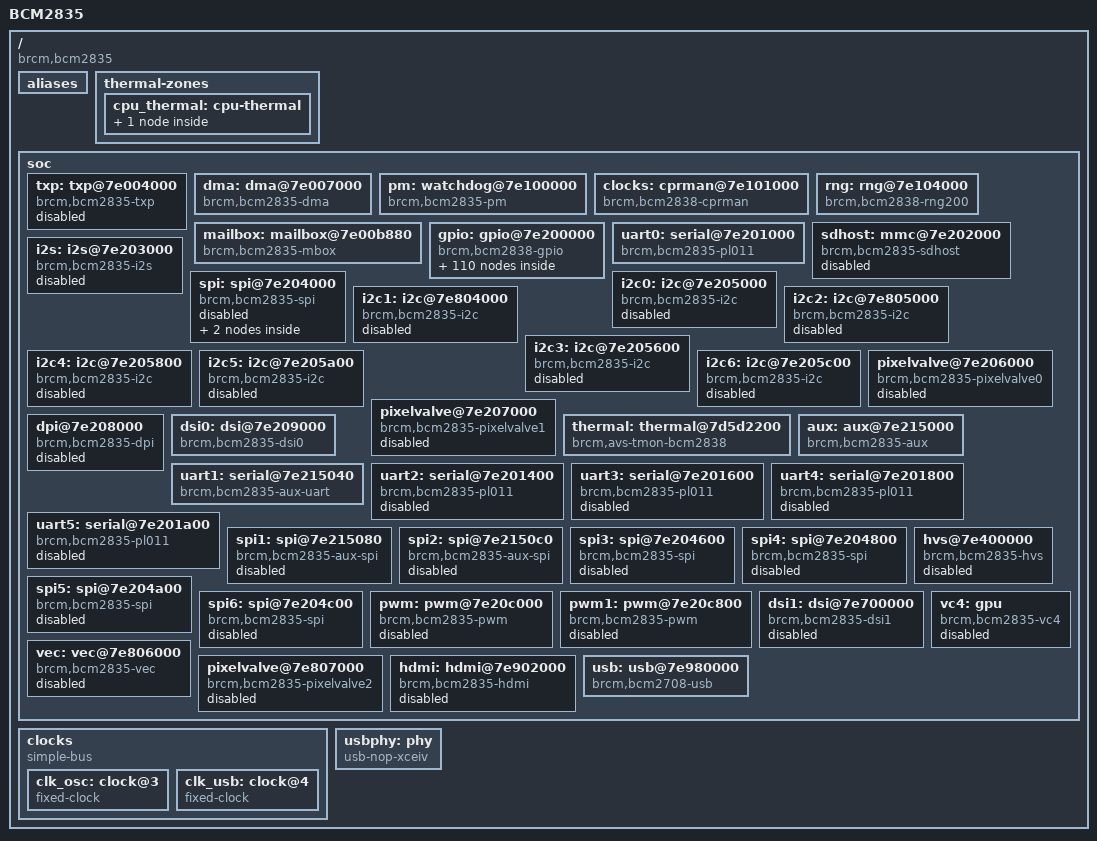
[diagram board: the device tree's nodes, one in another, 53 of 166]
#include <dt-bindings/pinctrl/bcm2835.h>
#include <dt-bindings/clock/bcm2835.h>
#include <dt-bindings/clock/bcm2835-aux.h>
#include <dt-bindings/gpio/gpio.h>
#include <dt-bindings/soc/bcm2835-pm.h>
#include <dt-bindings/interrupt-controller/arm-gic.h>
#include <dt-bindings/interrupt-controller/irq.h>
#include <dt-bindings/power/raspberrypi-power.h>

/* firmware-provided startup stubs live here, where the secondary CPUs are
 * spinning.
 */
/memreserve/ 0x00000000 0x00001000;
// /memreserve/	0x0000000000000000 0x0000000000001000;

/* This include file covers the common peripherals and configuration between
 * bcm2835 and bcm2836 implementations, leaving the CPU configuration to
 * bcm2835.dtsi and bcm2836.dtsi.
 */

/ {
	compatible = "brcm,bcm2835";
	model = "BCM2835";
	interrupt-parent = <&gicv2>;
	#address-cells = <2>;
	#size-cells = <1>;

	aliases {
		serial0 = &uart0;
		serial1 = &uart1;
	};

	// chosen {
	// 	stdout-path = "serial0:115200n8";
	// };

	thermal-zones {
		cpu_thermal: cpu-thermal {
			polling-delay-passive = <0>;
			polling-delay = <1000>;

			thermal-sensors = <&thermal>;

			coefficients = <(-487) 410040>;
			// phandle = < 0x30 >;

			// trips { // TODO:
			// 	cpu-crit {
			// 		temperature	= <80000>;
			// 		hysteresis	= <0>;
			// 		type		= "critical";
			// 	};
			// };

			cooling-maps {
			};
		};
	};

	soc {
		txp: txp@7e004000 {
			compatible = "brcm,bcm2835-txp";
			reg = < 0x7e004000 0x20 >;
			interrupts = <GIC_SPI 75 IRQ_TYPE_LEVEL_HIGH >;
			status = "disabled";
			// phandle = < 0x32 >;
		};


		dma: dma@7e007000 {
			compatible = "brcm,bcm2835-dma";
			reg = < 0x7e007000 0xb00 >;
			interrupts = <GIC_SPI 80 IRQ_TYPE_LEVEL_HIGH>, // 80
                         <GIC_SPI 81 IRQ_TYPE_LEVEL_HIGH>, // 81
                         <GIC_SPI 82 IRQ_TYPE_LEVEL_HIGH>, // 82
                         <GIC_SPI 83 IRQ_TYPE_LEVEL_HIGH>, // 83
                         <GIC_SPI 84 IRQ_TYPE_LEVEL_HIGH>, // 84
                         <GIC_SPI 85 IRQ_TYPE_LEVEL_HIGH>, // 85
                         <GIC_SPI 86 IRQ_TYPE_LEVEL_HIGH>, // 86
                         // 
                         <GIC_SPI 87 IRQ_TYPE_LEVEL_HIGH>, // 87
                         <GIC_SPI 87 IRQ_TYPE_LEVEL_HIGH>, // 87
                         //
                         <GIC_SPI 88 IRQ_TYPE_LEVEL_HIGH>, // 88
                         <GIC_SPI 88 IRQ_TYPE_LEVEL_HIGH>; // 88
			interrupt-names = "dma0", 
                              "dma1",
                              "dma2",
                              "dma3",
                              "dma4",
                              "dma5",
                              "dma6",
                              "dma7",
                              "dma8",
                              "dma9",
                              "dma10";

			#dma-cells = <1>;
			brcm,dma-channel-mask = < 0x1f5 >;
			// phandle = < 0x0a >;
		};

		pm: watchdog@7e100000 {
			compatible = "brcm,bcm2835-pm", "brcm,bcm2835-pm-wdt";
			#power-domain-cells = <1>;
			#reset-cells = <1>;
			reg = < 0x7e100000 0x114>,
			      < 0x7e00a000 0x24>,
				  < 0x7ec11000 0x20>;
			// clocks = < 0x03 0x15 0x03 0x1d 0x03 0x17 0x03 0x16 >;
			clocks = <&clocks BCM2835_CLOCK_V3D>,
				 <&clocks BCM2835_CLOCK_PERI_IMAGE>,
				 <&clocks BCM2835_CLOCK_H264>,
				 <&clocks BCM2835_CLOCK_ISP>;
			clock-names = "v3d", "peri_image", "h264", "isp";
			system-power-controller;
			// phandle = < 0x1d >;
		};

		clocks: cprman@7e101000 {
			compatible = "brcm,bcm2838-cprman";
			#clock-cells = <1>;
			reg = < 0x7e101000 0x2000 >;


			/* CPRMAN derives almost everything from the
			 * platform's oscillator.  However, the DSI
			 * pixel clocks come from the DSI analog PHY.
			 */	
			clocks = <&clk_osc>,
				<&dsi0 0>, <&dsi0 1>, <&dsi0 2>,
				<&dsi1 0>, <&dsi1 1>, <&dsi1 2>;			 
			// clocks = < 0x04 
			//            0x05 0x00 
			//            0x05 0x01 
			// 		   0x05 0x02 
					   
			// 		   0x06 0x00 
			// 		   0x06 0x01 
			// 		   0x06 0x02 >;

			firmware = <&firmware>;


			// phandle = < 0x03 >;
		};

		rng: rng@7e104000 {
			compatible = "brcm,bcm2838-rng200";
			reg = < 0x7e104000 0x10 >;
			interrupts = <GIC_SPI 125 IRQ_TYPE_LEVEL_HIGH>;
			// phandle = < 0x27 >;
		};

		mailbox: mailbox@7e00b880 {
			compatible = "brcm,bcm2835-mbox";
			reg = < 0x7e00b880 0x40 >;
			interrupts = <GIC_SPI 33 IRQ_TYPE_LEVEL_HIGH>;
			#mbox-cells = <0>;
			//phandle = < 0x1b >;
		};

		gpio: gpio@7e200000 {
			compatible = "brcm,bcm2838-gpio", "brcm,bcm2835-gpio";
			reg = < 0x7e200000 0xb4 >;
			/*
			 * The GPIO IP block is designed for 3 banks of GPIOs.
			 * Each bank has a GPIO interrupt for itself.
			 * There is an overall "any bank" interrupt.
			 * In order, these are GIC interrupts 17, 18, 19, 20.
			 * Since the BCM2835 only has 2 banks, the 2nd bank
			 * interrupt output appears to be mirrored onto the
			 * 3rd bank's interrupt signal.
			 * So, a bank0 interrupt shows up on 17, 20, and
			 * a bank1 interrupt shows up on 18, 19, 20!
			 */
			interrupts = <GIC_SPI 113 IRQ_TYPE_LEVEL_HIGH>,
                         <GIC_SPI 114 IRQ_TYPE_LEVEL_HIGH>;

			gpio-controller;
			#gpio-cells = <2>;

			interrupt-controller;
			#interrupt-cells = <2>;

			pinctrl-names = "default";
			// phandle = < 0x0f >;

			/* Defines pin muxing groups according to
			 * BCM2835-ARM-Peripherals.pdf page 102.
			 *
			 * While each pin can have its mux selected
			 * for various functions individually, some
			 * groups only make sense to switch to a
			 * particular function together.
			 */
			dpi_gpio0: dpi_gpio0 {
				brcm,pins = <0 1 2 3 4 5 6 7 8 9 10 11
					     12 13 14 15 16 17 18 19
					     20 21 22 23 24 25 26 27>;
				brcm,function = <BCM2835_FSEL_ALT2>;
				// phandle = < 0x33 >;
			};

			emmc_gpio22: emmc_gpio22 {
				brcm,pins = <22 23 24 25 26 27>;
				brcm,function = <BCM2835_FSEL_ALT3>;
				//phandle = < 0x34 >;
			};

			emmc_gpio34: emmc_gpio34 {
				brcm,pins = <34 35 36 37 38 39>;
				brcm,function = <BCM2835_FSEL_ALT3>;
				brcm,pull = <BCM2835_PUD_OFF
					     BCM2835_PUD_UP
					     BCM2835_PUD_UP
					     BCM2835_PUD_UP
					     BCM2835_PUD_UP
					     BCM2835_PUD_UP>;
				// phandle = < 0x35 >;
			};
            // ==========================================================
			emmc_gpio48: emmc_gpio48 {
				brcm,pins = <48 49 50 51 52 53>;
				brcm,function = <BCM2835_FSEL_ALT3>;
			};

			gpclk0_gpio4: gpclk0_gpio4 {
				brcm,pins = <4>;
				brcm,function = <BCM2835_FSEL_ALT0>;
			};

			gpclk1_gpio5: gpclk1_gpio5 {
				brcm,pins = <5>;
				brcm,function = <BCM2835_FSEL_ALT0>;
			};

			gpclk1_gpio42: gpclk1_gpio42 {
				brcm,pins = <42>;
				brcm,function = <BCM2835_FSEL_ALT0>;
			};

			gpclk1_gpio44: gpclk1_gpio44 {
				brcm,pins = <44>;
				brcm,function = <BCM2835_FSEL_ALT0>;
			};

			gpclk2_gpio6: gpclk2_gpio6 {
				brcm,pins = <6>;
				brcm,function = <BCM2835_FSEL_ALT0>;
			};

			gpclk2_gpio43: gpclk2_gpio43 {
				brcm,pins = <43>;
				brcm,function = <BCM2835_FSEL_ALT0>;
				brcm,pull = <BCM2835_PUD_OFF>;
			};

			i2c0_gpio0: i2c0_gpio0 {
				brcm,pins = <0 1>;
				brcm,function = <BCM2835_FSEL_ALT0>;
			};

			i2c0_gpio28: i2c0_gpio28 {
				brcm,pins = <28 29>;
				brcm,function = <BCM2835_FSEL_ALT0>;
			};

			i2c0_gpio44: i2c0_gpio44 {
				brcm,pins = <44 45>;
				brcm,function = <BCM2835_FSEL_ALT1>;
			};

			i2c1_gpio2: i2c1_gpio2 {
				brcm,pins = <2 3>;
				brcm,function = <BCM2835_FSEL_ALT0>;
			};

			i2c1_gpio44: i2c1_gpio44 {
				brcm,pins = <44 45>;
				brcm,function = <BCM2835_FSEL_ALT2>;
			};

			jtag_gpio22: jtag_gpio22 {
				brcm,pins = <22 23 24 25 26 27>;
				brcm,function = <BCM2835_FSEL_ALT4>;
			};

			pcm_gpio18: pcm_gpio18 {
				brcm,pins = <18 19 20 21>;
				brcm,function = <BCM2835_FSEL_ALT0>;
			};

			pcm_gpio28: pcm_gpio28 {
				brcm,pins = <28 29 30 31>;
				brcm,function = <BCM2835_FSEL_ALT2>;
			};

			pwm0_gpio12: pwm0_gpio12 {
				brcm,pins = <12>;
				brcm,function = <BCM2835_FSEL_ALT0>;
			};

			pwm0_gpio18: pwm0_gpio18 {
				brcm,pins = <18>;
				brcm,function = <BCM2835_FSEL_ALT5>;
			};

			pwm0_gpio40: pwm0_gpio40 {
				brcm,pins = <40>;
				brcm,function = <BCM2835_FSEL_ALT0>;
			};

			pwm1_gpio13: pwm1_gpio13 {
				brcm,pins = <13>;
				brcm,function = <BCM2835_FSEL_ALT0>;
			};

			pwm1_gpio19: pwm1_gpio19 {
				brcm,pins = <19>;
				brcm,function = <BCM2835_FSEL_ALT5>;
			};

			pwm1_gpio41: pwm1_gpio41 {
				brcm,pins = <41>;
				brcm,function = <BCM2835_FSEL_ALT0>;
			};

			pwm1_gpio45: pwm1_gpio45 {
				brcm,pins = <45>;
				brcm,function = <BCM2835_FSEL_ALT0>;
			};

			sdhost_gpio48: sdhost_gpio48 { // TODO: why? pin 22...
				brcm,pins = <22 23 24 25 26 27>;
				brcm,function = <BCM2835_FSEL_ALT0>;
			};

			spi0_gpio7: spi0_gpio7 {
				brcm,pins = <7 8 9 10 11>;
				brcm,function = <BCM2835_FSEL_ALT0>;
			};

			spi0_gpio35: spi0_gpio35 {
				brcm,pins = <35 36 37 38 39>;
				brcm,function = <BCM2835_FSEL_ALT0>;
			};

			spi1_gpio16: spi1_gpio16 {
				brcm,pins = <16 17 18 19 20 21>;
				brcm,function = <BCM2835_FSEL_ALT4>;
			};

			spi2_gpio40: spi2_gpio40 {
				brcm,pins = <40 41 42 43 44 45>;
				brcm,function = <BCM2835_FSEL_ALT4>;
			};

			uart0_gpio14: uart0_gpio14 {
				brcm,pins = <14 15>;
				brcm,function = <BCM2835_FSEL_ALT0>;
			};

			uart0_ctsrts_gpio16: uart0_ctsrts_gpio16 {
				brcm,pins = <16 17>;
				brcm,function = <BCM2835_FSEL_ALT3>;
			};

			uart0_ctsrts_gpio30: uart0_ctsrts_gpio30 {
				brcm,pins = <30 31>;
				brcm,function = <BCM2835_FSEL_ALT3>;
				brcm,pull = <BCM2835_PUD_UP BCM2835_PUD_OFF>;
			};

			uart0_gpio32: uart0_gpio32 {
				brcm,pins = <32 33>;
				brcm,function = <BCM2835_FSEL_ALT3>;
				brcm,pull = <BCM2835_PUD_OFF BCM2835_PUD_UP>;
			};

			uart0_gpio36: uart0_gpio36 {
				brcm,pins = <36 37>;
				brcm,function = <BCM2835_FSEL_ALT2>;
			};

			uart0_ctsrts_gpio38: uart0_ctsrts_gpio38 {
				brcm,pins = <38 39>;
				brcm,function = <BCM2835_FSEL_ALT2>;
			};

			uart1_gpio14: uart1_gpio14 {
				brcm,pins = <14 15>;
				brcm,function = <BCM2835_FSEL_ALT5>;
			};

			uart1_ctsrts_gpio16: uart1_ctsrts_gpio16 {
				brcm,pins = <16 17>;
				brcm,function = <BCM2835_FSEL_ALT5>;
			};

			uart1_gpio32: uart1_gpio32 {
				brcm,pins = <32 33>;
				brcm,function = <BCM2835_FSEL_ALT5>;
			};

			uart1_ctsrts_gpio30: uart1_ctsrts_gpio30 {
				brcm,pins = <30 31>;
				brcm,function = <BCM2835_FSEL_ALT5>;
			};

			uart1_gpio40: uart1_gpio40 {
				brcm,pins = <40 41>;
				brcm,function = <BCM2835_FSEL_ALT5>;
			};

			uart1_ctsrts_gpio42: uart1_ctsrts_gpio42 {
				brcm,pins = <42 43>;
				brcm,function = <BCM2835_FSEL_ALT5>;
			};

			gpclk0_gpio49: gpclk0_gpio49 {
				brcm,pins = <49>;
				brcm,function = <BCM2835_FSEL_ALT1>;
				brcm,pull = <BCM2835_PUD_OFF>;
			};

			gpclk1_gpio50: gpclk1_gpio50 {
				brcm,pins = <50>;
				brcm,function = <BCM2835_FSEL_ALT1>;
				brcm,pull = <BCM2835_PUD_OFF>;
			};

			gpclk2_gpio51: gpclk2_gpio51 {
				brcm,pins = <51>;
				brcm,function = <BCM2835_FSEL_ALT1>;
				brcm,pull = <BCM2835_PUD_OFF >;
			};

			i2c0_gpio46: i2c0_gpio46 {
				brcm,pins = <46 47>;
				brcm,function = <BCM2835_FSEL_ALT0>;
			};

			i2c1_gpio46: i2c1_gpio46 {
				brcm,pins = <46 47>;
				brcm,function = <BCM2835_FSEL_ALT1>;
			};

			i2c3_gpio2: i2c3_gpio2 {
				brcm,pins = <2 3>;
				brcm,function = <BCM2835_FSEL_ALT5>;
			};

			i2c3_gpio4: i2c3_gpio4 {
				brcm,pins = <4 5>;
				brcm,function = <BCM2835_FSEL_ALT5>;
			};

			i2c4_gpio6: i2c4_gpio6 {
				brcm,pins = <6 7>;
				brcm,function = <BCM2835_FSEL_ALT5>;
			};

			i2c4_gpio8: i2c4_gpio8 {
				brcm,pins = <8 9>;
				brcm,function = <BCM2835_FSEL_ALT5>;
			};

			i2c5_gpio10: i2c5_gpio10 {
				brcm,pins = <10 11>;
				brcm,function = <BCM2835_FSEL_ALT5>;
			};

			i2c5_gpio12: i2c5_gpio12 {
				brcm,pins = <12 13>;
				brcm,function = <BCM2835_FSEL_ALT5>;
			};

			i2c6_gpio0: i2c6_gpio0 {
				brcm,pins = <0 1>;
				brcm,function = <BCM2835_FSEL_ALT5>;
			};

			i2c6_gpio22: i2c6_gpio22 {
				brcm,pins = <22 23>;
				brcm,function = <BCM2835_FSEL_ALT5>;
			};

			i2c_slave_gpio8: i2c_slave_gpio8 {
				brcm,pins = <8 9 10 11>;
				brcm,function = <BCM2835_FSEL_ALT3>;
			};

			jtag_gpio48: jtag_gpio48 {
				brcm,pins = <48 49 50 51 52 53>;
				brcm,function = <BCM2835_FSEL_ALT4>;
			};

			mii_gpio28: mii_gpio28 {
				brcm,pins = <28 29 30 31>;
				brcm,function = <BCM2835_FSEL_ALT4>;
			};

			mii_gpio36: mii_gpio36 {
				brcm,pins = <36 37 38 39>;
				brcm,function = <BCM2835_FSEL_ALT5>;
			};

			pcm_gpio50: pcm_gpio50 {
				brcm,pins = <50 51 52 53>;
				brcm,function = <BCM2835_FSEL_ALT2>;
			};

			pwm0_gpio52: pwm0_gpio52 {
				brcm,pins = <52>;
				brcm,function = <BCM2835_FSEL_ALT1>;
				brcm,pull = <BCM2835_PUD_OFF >;
			};

			pwm1_gpio53: pwm1_gpio53 {
				brcm,pins = <53>;
				brcm,function = <BCM2835_FSEL_ALT1>;
				brcm,pull = <BCM2835_PUD_OFF >;
			};

			rgmii_gpio35: rgmii_gpio35 {
				brcm,pins = <35 36>;
				brcm,function = <BCM2835_FSEL_ALT4>;
			};

			rgmii_irq_gpio34: rgmii_irq_gpio34 {
				brcm,pins = <34>;
				brcm,function = <BCM2835_FSEL_ALT5>;
			};

			rgmii_irq_gpio39: rgmii_irq_gpio39 {
				brcm,pins = <39>;
				brcm,function = <BCM2835_FSEL_ALT4>;
			};

			rgmii_mdio_gpio28: rgmii_mdio_gpio28 {
				brcm,pins = <28 29>;
				brcm,function = <BCM2835_FSEL_ALT5>;
			};

			rgmii_mdio_gpio37: rgmii_mdio_gpio37 {
				brcm,pins = <37 38>;
				brcm,function = <BCM2835_FSEL_ALT4>;
			};

			spi0_gpio46: spi0_gpio46 {
				brcm,pins = <46 47 48 49>;
				brcm,function = <BCM2835_FSEL_ALT2>;
			};

			spi2_gpio46: spi2_gpio46 {
				brcm,pins = <46 47 48 49 50>; // TODO: why 5 ???
				brcm,function = <BCM2835_FSEL_ALT5>;
			};

			spi3_gpio0: spi3_gpio0 {
				brcm,pins = <0 1 2 3>;
				brcm,function = <BCM2835_FSEL_ALT3>;
			};

			spi4_gpio4: spi4_gpio4 {
				brcm,pins = <4 5 6 7>;
				brcm,function = <BCM2835_FSEL_ALT3>;
			};

			spi5_gpio12: spi5_gpio12 {
				brcm,pins = <12 13 14 15>;
				brcm,function = <BCM2835_FSEL_ALT3>;
			};

			spi6_gpio18: spi6_gpio18 {
				brcm,pins = <18 19 20 21>;
				brcm,function = <BCM2835_FSEL_ALT3>;
			};

			uart2_gpio0: uart2_gpio0 {
				brcm,pins = <0 1>;
				brcm,function = <BCM2835_FSEL_ALT4>;
				brcm,pull = <BCM2835_PUD_OFF BCM2835_PUD_UP>;
			};

			uart2_ctsrts_gpio2: uart2_ctsrts_gpio2 {
				brcm,pins = <2 3>;
				brcm,function = <BCM2835_FSEL_ALT4>;
				brcm,pull = <BCM2835_PUD_UP BCM2835_PUD_OFF>;
			};

			uart3_gpio4: uart3_gpio4 {
				brcm,pins = <4 5>;
				brcm,function = <BCM2835_FSEL_ALT4>;
				brcm,pull = <BCM2835_PUD_OFF BCM2835_PUD_UP>;
			};

			uart3_ctsrts_gpio6: uart3_ctsrts_gpio6 {
				brcm,pins = <6 7>;
				brcm,function = <BCM2835_FSEL_ALT4>;
				brcm,pull = <BCM2835_PUD_UP BCM2835_PUD_OFF>;
			};

			uart4_gpio8: uart4_gpio8 {
				brcm,pins = <8 9>;
				brcm,function = <BCM2835_FSEL_ALT4>;
				brcm,pull = <BCM2835_PUD_OFF BCM2835_PUD_UP>;
			};

			uart4_ctsrts_gpio10: uart4_ctsrts_gpio10 {
				brcm,pins = <10 11>;
				brcm,function = <BCM2835_FSEL_ALT4>;
				brcm,pull = <BCM2835_PUD_UP BCM2835_PUD_OFF>;
			};

			uart5_gpio12: uart5_gpio12 {
				brcm,pins = <12 13>;
				brcm,function = <BCM2835_FSEL_ALT4>;
				brcm,pull = <BCM2835_PUD_OFF BCM2835_PUD_UP>;
			};

			uart5_ctsrts_gpio14: uart5_ctsrts_gpio14 {
				brcm,pins = <14 15>;
				brcm,function = <BCM2835_FSEL_ALT4>;
				brcm,pull = <BCM2835_PUD_UP BCM2835_PUD_OFF>;
			};

			dpi_18bit_gpio0: dpi_18bit_gpio0 {
				brcm,pins = <0 1 2 3 4 5 6 7 8 9 10 11 12 13 14 15 16 17 18 19 20 21>; //TODO: why 22 ??
				brcm,function = <BCM2835_FSEL_ALT2>;
			};

			gpioout: gpioout {
				brcm,pins = <6>;
				brcm,function = <BCM2835_FSEL_GPIO_OUT>;
			};

			alt0: alt0 {
				brcm,pins = <4 5 7 8 9 10 11>;
				brcm,function = <BCM2835_FSEL_ALT0>;
			};

			spi0_pins: spi0_pins {
				brcm,pins = <9 10 11>;
				brcm,function = <BCM2835_FSEL_ALT0>;
			};

			spi0_cs_pins: spi0_cs_pins {
				brcm,pins = <8 7>;
				brcm,function = <BCM2835_FSEL_GPIO_OUT>;
			};

			spi3_pins: spi3_pins {
				brcm,pins = <1 2 3>;
				brcm,function = <BCM2835_FSEL_ALT3>;
			};

			spi3_cs_pins: spi3_cs_pins {
				brcm,pins = <0 24>;
				brcm,function = <BCM2835_FSEL_GPIO_OUT>;
			};

			spi4_pins: spi4_pins {
				brcm,pins = <5 6 7>;
				brcm,function = <BCM2835_FSEL_ALT3>;
			};

			spi4_cs_pins: spi4_cs_pins {
				brcm,pins = <4 25>;
				brcm,function = <BCM2835_FSEL_GPIO_OUT>;
			};

			spi5_pins: spi5_pins {
				brcm,pins = <13 14 15>;
				brcm,function = <BCM2835_FSEL_ALT3>;
			};

			spi5_cs_pins: spi5_cs_pins {
				brcm,pins = <12 26>;
				brcm,function = <BCM2835_FSEL_GPIO_OUT>;
			};

			spi6_pins: spi6_pins {
				brcm,pins = <19 20 21>;
				brcm,function = <BCM2835_FSEL_ALT3>;

			};

			spi6_cs_pins: spi6_cs_pins {
				brcm,pins = <18 27>;
				brcm,function = <BCM2835_FSEL_GPIO_OUT>;
			};

			i2c0_pins: i2c0 {
				brcm,pins = <0 1>;
				brcm,function = <BCM2835_FSEL_ALT0>;
			};

			i2c1_pins: i2c1 {
				brcm,pins = <2 3>;
				brcm,function = <BCM2835_FSEL_ALT0>;
			};

			i2c3_pins: i2c3 {
				brcm,pins = <4 5>;
				brcm,function = <BCM2835_FSEL_ALT5>;
			};

			i2c4_pins: i2c4 {
				brcm,pins = <8 9>;
				brcm,function = <BCM2835_FSEL_ALT5>;
			};

			i2c5_pins: i2c5 {
				brcm,pins = <12 13>;
				brcm,function = <BCM2835_FSEL_ALT5>;
			};

			i2c6_pins: i2c6 {
				brcm,pins = <22 23>;
				brcm,function = <BCM2835_FSEL_ALT5>;
			};

			i2s_pins: i2s {
				brcm,pins = <18 19 20 21>;
				brcm,function = <BCM2835_FSEL_ALT0>;
			};

			sdio_pins: sdio_pins {
				brcm,pins = <34 35 36 37 38 39>;
				brcm,function = <BCM2835_FSEL_ALT3>;
				brcm,pull = <BCM2835_PUD_OFF 
                             BCM2835_PUD_UP
                             BCM2835_PUD_UP
                             BCM2835_PUD_UP
                             BCM2835_PUD_UP
                             BCM2835_PUD_UP>;
			};

			bt_pins: bt_pins {
				brcm,pins = [ 2d 00 ]; //TODO: check ??
				brcm,function = <BCM2835_FSEL_GPIO_IN>;
				brcm,pull = <BCM2835_PUD_UP>;
			};

			uart0_pins: uart0_pins {
				brcm,pins = <32 33>;
				brcm,function = <BCM2835_FSEL_ALT3>;
				brcm,pull = <BCM2835_PUD_OFF BCM2835_PUD_UP>;
			};

			uart1_pins: uart1_pins {
				brcm,pins; // = <>; // TODO: check ??
				brcm,function; // = <BCM2835_FSEL_ALT4>;
				brcm,pull; // = <BCM2835_PUD_OFF BCM2835_PUD_UP>;;
			};

			uart2_pins: uart2_pins {
				brcm,pins = <0 1>;
				brcm,function = <BCM2835_FSEL_ALT4>;
				brcm,pull = <BCM2835_PUD_OFF BCM2835_PUD_UP>;
			};

			uart3_pins: uart3_pins {
				brcm,pins = <4 5>;
				brcm,function = <BCM2835_FSEL_ALT4>;
				brcm,pull = <BCM2835_PUD_OFF BCM2835_PUD_UP>;
			};

			uart4_pins: uart4_pins {
				brcm,pins = <8 9>;
				brcm,function = <BCM2835_FSEL_ALT4>;
				brcm,pull = <BCM2835_PUD_OFF BCM2835_PUD_UP>;
			};

			uart5_pins: uart5_pins {
				brcm,pins = <12 13>;
				brcm,function = <BCM2835_FSEL_ALT4>;
				brcm,pull = <BCM2835_PUD_OFF BCM2835_PUD_UP>;
			};

			audio_pins: audio_pins {
				brcm,pins = <40 41>;
				brcm,function = <BCM2835_FSEL_ALT0>;
			};
		};

        uart0: serial@7e201000 {
			compatible = "brcm,bcm2835-pl011", "arm,pl011", "arm,primecell";
			reg = < 0x7e201000 0x200 >;
			interrupts = <GIC_SPI 121 IRQ_TYPE_LEVEL_HIGH>;
			// clocks = < 0x03 0x13 0x03 0x14 >;
			clocks = <&clocks BCM2835_CLOCK_UART>,
				 <&clocks BCM2835_CLOCK_VPU>;
			clock-names = "uartclk", "apb_pclk";
			arm,primecell-periphid = < 0x241011 >;
			cts-event-workaround;
			pinctrl-names = "default";
			pinctrl-0 = <&uart0_pins &bt_pins>;
			status = "okay";
			// phandle = < 0x20 >;
		};

		sdhost: mmc@7e202000 {
			compatible = "brcm,bcm2835-sdhost";
			reg = < 0x7e202000 0x100 >;
			interrupts = <GIC_SPI 120 IRQ_TYPE_LEVEL_HIGH>;
			clocks = <&clocks BCM2835_CLOCK_VPU>;
			dmas = <&dma 0x2000000d>; // TODO: <&dma 13> ???
			dma-names = "rx-tx";
			status = "disabled";

			pinctrl-names = "default";
			pinctrl-0 = <&sdhost_gpio48>;
			bus-width = < 0x04 >;
			brcm,overclock-50 = < 0x00 >;
			brcm,pio-limit = < 0x01 >;
			// phandle = < 0x28 >;
		};        

		i2s: i2s@7e203000 {
			compatible = "brcm,bcm2835-i2s";
			reg = < 0x7e203000 0x24 >;
			clocks = <&clocks BCM2835_CLOCK_PCM>;

			dmas = <&dma 2>,
			       <&dma 3>;
			dma-names = "tx", "rx";
			status = "disabled";

			#sound-dai-cells = <0>;
			pinctrl-names = "default";
			pinctrl-0 = <&i2s_pins>;
			// phandle = < 0x22 >;
		};



		spi: spi@7e204000 {
			compatible = "brcm,bcm2835-spi";
			reg = < 0x7e204000 0x200 >;
			interrupts = <GIC_SPI 118 IRQ_TYPE_LEVEL_HIGH>;
			clocks = <&clocks BCM2835_CLOCK_VPU>;
			#address-cells = <1>;
			#size-cells = <0>;
			status = "disabled";

			dmas = <&dma 6>,
			       <&dma 7>;
			dma-names = "tx", "rx";
			
			pinctrl-names = "default";
			pinctrl-0 = <&spi0_pins &spi0_cs_pins>;
			cs-gpios = <&gpio 8 GPIO_ACTIVE_LOW >,
			           <&gpio 7 GPIO_ACTIVE_LOW >;
			// phandle = < 0x23 >;

			spidev@0 {
				compatible = "spidev";
				reg = < 0x00 >;
				#address-cells = <1>;
				#size-cells = <0>;
				spi-max-frequency = <125000000>;
				// phandle = < 0x95 >;
			};

			spidev@1 {
				compatible = "spidev";
				reg = < 0x01 >;
				#address-cells = <1>;
				#size-cells = <0>;
				spi-max-frequency = <125000000>;
				// phandle = < 0x96 >;
			};
		};


        i2c0: i2c@7e205000 {
			compatible = "brcm,bcm2835-i2c";
			reg = < 0x7e205000 0x200 >;
			interrupts = <GIC_SPI 117 IRQ_TYPE_LEVEL_HIGH>;
			clocks =<&clocks BCM2835_CLOCK_VPU>;
			#address-cells = <1>;
			#size-cells = <0>;
			status = "disabled";
			pinctrl-names = "default";
			pinctrl-0 = <&i2c0_pins>;
			clock-frequency = <100000>;
			// phandle = < 0x24 >;
		};

		i2c1: i2c@7e804000 {
			compatible = "brcm,bcm2835-i2c";
			reg = < 0x7e804000 0x1000 >;
			interrupts = <GIC_SPI 117 IRQ_TYPE_LEVEL_HIGH>;
			clocks = <&clocks BCM2835_CLOCK_VPU>;
			#address-cells = <1>;
			#size-cells = <0>;
			status = "disabled";
			pinctrl-names = "default";
			pinctrl-0 = <&i2c1_pins>;
			clock-frequency = <100000>;
			// phandle = < 0x25 >;
		};

		i2c2: i2c@7e805000 {
			compatible = "brcm,bcm2835-i2c";
			reg = < 0x7e805000 0x1000 >;
			interrupts = <GIC_SPI 117 IRQ_TYPE_LEVEL_HIGH>;
			clocks = <&clocks BCM2835_CLOCK_VPU>;
			#address-cells = <1>;
			#size-cells = <0>;
			status = "disabled";
			clock-frequency = <100000>;
			// phandle = < 0x15 >;
		};

		i2c3: i2c@7e205600 {
			compatible = "brcm,bcm2835-i2c";
			reg = < 0x7e205600 0x200 >;
			interrupts = <GIC_SPI 117 IRQ_TYPE_LEVEL_HIGH>;
			clocks = <&clocks BCM2835_CLOCK_VPU>;
			#address-cells = <1>;
			#size-cells = <0>;
			status = "disabled";
			// phandle = < 0xae >;
		};

		i2c4: i2c@7e205800 {
			compatible = "brcm,bcm2835-i2c";
			reg = < 0x7e205800 0x200 >;
			interrupts = <GIC_SPI 117 IRQ_TYPE_LEVEL_HIGH>;
			clocks = <&clocks BCM2835_CLOCK_VPU>;
			#address-cells = <1>;
			#size-cells = <0>;
			status = "disabled";
			// phandle = < 0xaf >;
		};

		i2c5: i2c@7e205a00 {
			compatible = "brcm,bcm2835-i2c";
			reg = < 0x7e205a00 0x200 >;
			interrupts = <GIC_SPI 117 IRQ_TYPE_LEVEL_HIGH>;
			clocks = <&clocks BCM2835_CLOCK_VPU>;
			#address-cells = <1>;
			#size-cells = <0>;
			status = "disabled";
			// phandle = < 0xb0 >;
		};

		i2c6: i2c@7e205c00 {
			compatible = "brcm,bcm2835-i2c";
			reg = < 0x7e205c00 0x200 >;
			interrupts = <GIC_SPI 117 IRQ_TYPE_LEVEL_HIGH>;
			clocks = <&clocks BCM2835_CLOCK_VPU>;
			#address-cells = <1>;
			#size-cells = <0>;
			status = "disabled";
			// phandle = < 0xb1 >;
		};

		pixelvalve@7e206000 {
			compatible = "brcm,bcm2835-pixelvalve0";
			reg = < 0x7e206000 0x100 >;
			interrupts = <GIC_SPI 109 IRQ_TYPE_LEVEL_HIGH>; /* pwa0 */
			status = "disabled";
			// phandle = < 0x97 >;
		};

		pixelvalve@7e207000 {
			compatible = "brcm,bcm2835-pixelvalve1";
			reg = < 0x7e207000 0x100 >;
			interrupts = <GIC_SPI 110 IRQ_TYPE_LEVEL_HIGH>; /* pwa1 */
			status = "disabled";
			// phandle = < 0x98 >;
		};

		dpi@7e208000 {
			compatible = "brcm,bcm2835-dpi";
			reg = < 0x7e208000 0x8c >;
			clocks = <&clocks BCM2835_CLOCK_VPU>,
				     <&clocks BCM2835_CLOCK_DPI>;
			clock-names = "core", "pixel";
			#address-cells = <1>;
			#size-cells = <0>;
			status = "disabled";
			// phandle = < 0x99 >;
		};

		dsi0: dsi@7e209000 {
			compatible = "brcm,bcm2835-dsi0";
			reg = < 0x7e209000 0x78 >;
			interrupts = <GIC_SPI 100 IRQ_TYPE_LEVEL_HIGH>;
			#address-cells = <1>;
			#size-cells = <0>;
			#clock-cells = <1>;
			
			// clocks = < 0x03 0x20 0x03 0x2f 0x03 0x31 >;
            clocks = <&clocks BCM2835_PLLA_DSI0>,
				 <&clocks BCM2835_CLOCK_DSI0E>,
				 <&clocks BCM2835_CLOCK_DSI0P>;
			
			clock-names = "phy", "escape", "pixel";
			
			clock-output-names = "dsi0_byte", "dsi0_ddr2", "dsi0_ddr";

			power-domains = <&power RPI_POWER_DOMAIN_DSI0>;
			// phandle = < 0x05 >;
		};

		thermal: thermal@7d5d2200 {
			compatible = "brcm,avs-tmon-bcm2838";
			reg = < 0x7d5d2200 0x2c >;
			interrupts = <GIC_SPI 137 IRQ_TYPE_LEVEL_HIGH>;
			interrupt-names = "tmon";
			clocks = <&clocks BCM2835_CLOCK_TSENS>;
			#thermal-sensor-cells = <0>;
			status = "okay";
			// phandle = < 0x02 >;
		};

        aux: aux@7e215000 {
			compatible = "brcm,bcm2835-aux";
			#clock-cells = <1>;
			reg = < 0x7e215000 0x08 >;
			clocks = <&clocks BCM2835_CLOCK_VPU>;
			// phandle = < 0x12 >;
		};

		uart1: serial@7e215040 {
			compatible = "brcm,bcm2835-aux-uart";
			reg = < 0x7e215040 0x40 >;
			interrupts = <GIC_SPI 93 IRQ_TYPE_LEVEL_HIGH>;
			clocks = <&aux BCM2835_AUX_CLOCK_UART>;
			status = "okay";
			pinctrl-names = "default";
			pinctrl-0 = <&uart1_pins>;
			// phandle = < 0x21 >;
		};

		uart2: serial@7e201400 {
			compatible = "brcm,bcm2835-pl011", "arm,pl011", "arm,primecell";
			reg = < 0x7e201400 0x200 >;
			interrupts = <GIC_SPI 121 IRQ_TYPE_LEVEL_HIGH>;
			clocks = <&clocks BCM2835_CLOCK_UART>,
			         <&clocks BCM2835_CLOCK_VPU>;
			clock-names = "uartclk", "apb_pclk";
			arm,primecell-periphid = < 0x241011 >;
			status = "disabled";
			// phandle = < 0xa6 >;
		};

		uart3: serial@7e201600 {
			compatible = "brcm,bcm2835-pl011", "arm,pl011", "arm,primecell";
			reg = < 0x7e201600 0x200 >;
			interrupts = <GIC_SPI 121 IRQ_TYPE_LEVEL_HIGH>;
			clocks = <&clocks BCM2835_CLOCK_UART>,
			         <&clocks BCM2835_CLOCK_VPU>;
			clock-names = "uartclk", "apb_pclk";
			arm,primecell-periphid = < 0x241011 >;
			status = "disabled";
			// phandle = < 0xa7 >;
		};

		uart4: serial@7e201800 {
			compatible = "brcm,bcm2835-pl011", "arm,pl011", "arm,primecell";
			reg = < 0x7e201800 0x200 >;
			interrupts = <GIC_SPI 121 IRQ_TYPE_LEVEL_HIGH>;
			clocks = <&clocks BCM2835_CLOCK_UART>,
			         <&clocks BCM2835_CLOCK_VPU>;
			clock-names = "uartclk", "apb_pclk";
			arm,primecell-periphid = < 0x241011 >;
			status = "disabled";
			// phandle = < 0xa8 >;
		};

		uart5: serial@7e201a00 {
			compatible = "brcm,bcm2835-pl011", "arm,pl011", "arm,primecell";
			reg = < 0x7e201a00 0x200 >;
			interrupts = <GIC_SPI 121 IRQ_TYPE_LEVEL_HIGH>;
			clocks = <&clocks BCM2835_CLOCK_UART>,
			         <&clocks BCM2835_CLOCK_VPU>;
			clock-names = "uartclk", "apb_pclk";
			arm,primecell-periphid = < 0x241011 >;
			status = "disabled";
			// phandle = < 0xa9 >;
		};

		spi1: spi@7e215080 {
			compatible = "brcm,bcm2835-aux-spi";
			reg = < 0x7e215080 0x40 >;
			interrupts = <GIC_SPI 93 IRQ_TYPE_LEVEL_HIGH>;
			clocks = <&aux BCM2835_AUX_CLOCK_SPI1>;
			#address-cells = <1>;
			#size-cells = <0>;
			status = "disabled";
			// phandle = < 0x9a >;
		};

		spi2: spi@7e2150c0 {
			compatible = "brcm,bcm2835-aux-spi";
			reg = < 0x7e2150c0 0x40 >;
			interrupts = <GIC_SPI 93 IRQ_TYPE_LEVEL_HIGH>;
			clocks = <&aux BCM2835_AUX_CLOCK_SPI2>;
			#address-cells = <1>;
			#size-cells = <0>;
			status = "disabled";
			// phandle = < 0x9b >;
		};

		spi3: spi@7e204600 {
			compatible = "brcm,bcm2835-spi";
			reg = < 0x7e204600 0x200 >;
			interrupts = <GIC_SPI 118 IRQ_TYPE_LEVEL_HIGH>;
			clocks = <&clocks BCM2835_CLOCK_VPU>;
			#address-cells = <1>;
			#size-cells = <0>;
			status = "disabled";
			// phandle = < 0xaa >;
		};

		spi4: spi@7e204800 {
			compatible = "brcm,bcm2835-spi";
			reg = < 0x7e204800 0x200 >;
			interrupts = <GIC_SPI 118 IRQ_TYPE_LEVEL_HIGH>;
			clocks = <&clocks BCM2835_CLOCK_VPU>;
			#address-cells = <1>;
			#size-cells = <0>;
			status = "disabled";
			// phandle = < 0xab >;
		};

		spi5: spi@7e204a00 {
			compatible = "brcm,bcm2835-spi";
			reg = < 0x7e204a00 0x200 >;
			interrupts = <GIC_SPI 118 IRQ_TYPE_LEVEL_HIGH>;
			clocks = <&clocks BCM2835_CLOCK_VPU>;
			#address-cells = <1>;
			#size-cells = <0>;
			status = "disabled";
			// phandle = < 0xac >;
		};

		spi6: spi@7e204c00 {
			compatible = "brcm,bcm2835-spi";
			reg = < 0x7e204c00 0x200 >;
			interrupts = <GIC_SPI 118 IRQ_TYPE_LEVEL_HIGH>;
			clocks = <&clocks BCM2835_CLOCK_VPU>;
			#address-cells = <1>;
			#size-cells = <0>;
			status = "disabled";
			// phandle = < 0xad >;
		};

		pwm: pwm@7e20c000 {
			compatible = "brcm,bcm2835-pwm";
			reg = < 0x7e20c000 0x28 >;
			clocks = <&clocks BCM2835_CLOCK_PWM>;
			assigned-clocks = <&clocks BCM2835_CLOCK_PWM>;
			assigned-clock-rates = <10000000>;
			#pwm-cells = <2>;
			status = "disabled";
			// phandle = < 0x9c >;
		};

		pwm1: pwm@7e20c800 {
			compatible = "brcm,bcm2835-pwm";
			reg = < 0x7e20c800 0x28 >;
			clocks = <&clocks BCM2835_CLOCK_PWM>;
			assigned-clocks = <&clocks BCM2835_CLOCK_PWM>;
			assigned-clock-rates = <10000000>;
			#pwm-cells = <2>;
			status = "disabled";
			// phandle = < 0xb2 >;
		};
        
		hvs@7e400000 {
			compatible = "brcm,bcm2835-hvs";
			reg = < 0x7e400000 0x6000 >;
			interrupts = <GIC_SPI 97 IRQ_TYPE_LEVEL_HIGH>;
			status = "disabled";
			// phandle = < 0x9d >;
		};

		dsi1: dsi@7e700000 {
			compatible = "brcm,bcm2835-dsi1";
			reg = < 0x7e700000 0x8c >;
			interrupts = <GIC_SPI 108 IRQ_TYPE_LEVEL_HIGH>;
			#address-cells = <1>;
			#size-cells = <0>;
			#clock-cells = <1>;

			// clocks = < 0x03 0x23 0x03 0x30 0x03 0x32 >;
			clocks = <&clocks BCM2835_PLLD_DSI1>,
				 <&clocks BCM2835_CLOCK_DSI1E>,
				 <&clocks BCM2835_CLOCK_DSI1P>;

			clock-names = "phy", "escape", "pixel";
			clock-output-names = "dsi1_byte", "dsi1_ddr2", "dsi1_ddr";
			status = "disabled";
			power-domains = <&power RPI_POWER_DOMAIN_DSI1>;
			// phandle = < 0x06 >;
		};

		vec: vec@7e806000 {
			compatible = "brcm,bcm2835-vec";
			reg = < 0x7e806000 0x1000 >;
			clocks =  <&clocks BCM2835_CLOCK_VEC>;
			interrupts = <GIC_SPI 123 IRQ_TYPE_LEVEL_HIGH>; 
			status = "disabled";
			power-domains = <&power RPI_POWER_DOMAIN_VEC>;
			// phandle = < 0xa0 >;
		};

		pixelvalve@7e807000 {
			compatible = "brcm,bcm2835-pixelvalve2";
			reg = < 0x7e807000 0x100 >;
			interrupts = <GIC_SPI 106 IRQ_TYPE_LEVEL_HIGH>; /* pixelvalve */
			status = "disabled";
			// phandle = < 0xa1 >;
		};

		hdmi: hdmi@7e902000 {
			compatible = "brcm,bcm2835-hdmi";
			reg = < 0x7e902000 0x600 >, 
			      < 0x7e808000 0x100 >;
			interrupts = <GIC_SPI 104 IRQ_TYPE_LEVEL_HIGH>, 
			             <GIC_SPI 105 IRQ_TYPE_LEVEL_HIGH>;
			ddc = < 0x15 >;
			clocks = <&clocks BCM2835_PLLH_PIX>,
			         <&clocks BCM2835_CLOCK_HSM>;
			clock-names = "pixel", "hdmi";
			dmas = <&dma 17>;
			dma-names = "audio-rx";
			status = "disabled";
			power-domains = <&power RPI_POWER_DOMAIN_HDMI>;
			// phandle = < 0xa2 >;
		};

		usb: usb@7e980000 {
			compatible = "brcm,bcm2708-usb";
			reg = < 0x7e980000 0x10000 0x7e00b200 0x200 >;
			interrupts = <GIC_SPI 73 IRQ_TYPE_LEVEL_HIGH>, 
			             <GIC_SPI 40 IRQ_TYPE_LEVEL_HIGH>;
			#address-cells = <1>;
			#size-cells = <0>;
			clocks = <&clk_usb>;
			clock-names = "otg";
			phys = <&usbphy>;
			phy-names = "usb2-phy";
			interrupt-names = "usb", "soft";
			power-domains = <&power RPI_POWER_DOMAIN_USB>;
			// phandle = < 0xa3 >;
		};

		vc4: gpu {
			compatible = "brcm,bcm2835-vc4";
			status = "disabled";
			// phandle = < 0xa4 >;
		};
	};

	clocks {
		compatible = "simple-bus";
		#address-cells = <1>;
		#size-cells = <0>;

		/* The oscillator is the root of the clock tree. */
		clk_osc: clock@3 {
			compatible = "fixed-clock";
			reg = <3>;
			#clock-cells = <0>;
			clock-output-names = "osc";
			clock-frequency = <54000000>;
			//phandle = < 0x04 >;
		};

		clk_usb: clock@4 {
			compatible = "fixed-clock";
			reg = <4>;
			#clock-cells = <0>;
			clock-output-names = "otg";
			clock-frequency = <480000000>;
			//phandle = < 0x16 >;
		};
	};

	usbphy: phy {
		compatible = "usb-nop-xceiv";
		#phy-cells = <0>;
		// phandle = < 0x17 >;
	};
};
